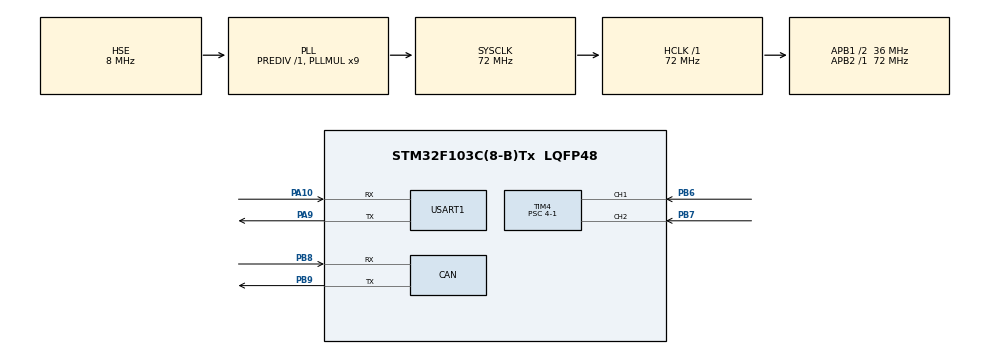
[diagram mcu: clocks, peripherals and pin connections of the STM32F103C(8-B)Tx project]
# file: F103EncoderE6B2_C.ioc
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CAN.CalculateTimeBit=1333
CAN.CalculateTimeQuantum=444.44444444444446
Mcu.Family=STM32F1
Mcu.Name=STM32F103C(8-B)Tx
Mcu.Package=LQFP48
NVIC.CAN1_RX1_IRQn=true\:1\:2\:true\:false\:true\:true\:true
NVIC.PriorityGroup=NVIC_PRIORITYGROUP_2
NVIC.TIM3_IRQn=true\:2\:2\:true\:false\:true\:true\:true
NVIC.TIM4_IRQn=true\:1\:3\:true\:false\:true\:true\:true
PA10.Mode=Asynchronous
PA10.Signal=USART1_RX
PA13.Mode=Serial_Wire
PA13.Signal=SYS_JTMS-SWDIO
PA14.Mode=Serial_Wire
PA14.Signal=SYS_JTCK-SWCLK
PA9.Mode=Asynchronous
PA9.Signal=USART1_TX
PB6.GPIO_PuPd=GPIO_PULLUP
PB6.Signal=S_TIM4_CH1
PB7.GPIO_PuPd=GPIO_PULLUP
PB7.Signal=S_TIM4_CH2
PB8.Mode=Master
PB8.Signal=CAN_RX
PB9.Mode=Master
PB9.Signal=CAN_TX
PD0-OSC_IN.Mode=HSE-External-Oscillator
PD0-OSC_IN.Signal=RCC_OSC_IN
PD1-OSC_OUT.Mode=HSE-External-Oscillator
PD1-OSC_OUT.Signal=RCC_OSC_OUT
ProjectManager.HeapSize=0x200
ProjectManager.StackSize=0x400
ProjectManager.TargetToolchain=MDK-ARM V5
RCC.AHBFreq_Value=72000000
RCC.APB1CLKDivider=RCC_HCLK_DIV2
RCC.APB1Freq_Value=36000000
RCC.APB1TimFreq_Value=72000000
RCC.APB2Freq_Value=72000000
RCC.APB2TimFreq_Value=72000000
RCC.HCLKFreq_Value=72000000
RCC.PLLMUL=RCC_PLL_MUL9
RCC.PLLSourceVirtual=RCC_PLLSOURCE_HSE
RCC.SYSCLKFreq_VALUE=72000000
RCC.SYSCLKSource=RCC_SYSCLKSOURCE_PLLCLK
RCC.USBFreq_Value=72000000
SH.S_TIM4_CH1.0=TIM4_CH1,Encoder_Interface
SH.S_TIM4_CH2.0=TIM4_CH2,Encoder_Interface
TIM3.AutoReloadPreload=TIM_AUTORELOAD_PRELOAD_ENABLE
TIM3.Period=10000
TIM3.Prescaler=72-1
TIM4.CounterMode=TIM_COUNTERMODE_UP
TIM4.EncoderMode=TIM_ENCODERMODE_TI12
TIM4.Period=65535
TIM4.Prescaler=4-1
USART1.VirtualMode=VM_ASYNC
VP_TIM3_VS_ClockSourceINT.Mode=Internal
board=custom

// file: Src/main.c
/* USER CODE BEGIN Header */
/**
  ******************************************************************************
  * @file           : main.c
  * @brief          : Main program body
  ******************************************************************************
  * @attention
  *
  * <h2><center>&copy; Copyright (c) 2020 STMicroelectronics.
  * All rights reserved.</center></h2>
  *
  * This software component is licensed by ST under BSD 3-Clause license,
  * the "License"; You may not use this file except in compliance with the
  * License. You may obtain a copy of the License at:
  *                        opensource.org/licenses/BSD-3-Clause
  *
  ******************************************************************************
  */
/* USER CODE END Header */

#include "main.h"

/* USER CODE BEGIN Includes */
#include "encoderE6B2.h"
/* USER CODE END Includes */

CAN_HandleTypeDef hcan;

TIM_HandleTypeDef htim3;
TIM_HandleTypeDef htim4;

UART_HandleTypeDef huart1;

/* USER CODE BEGIN PV */
	uint16_t cnt = 0;
	uint8_t string1[] = {"hello\r\n"};
/* USER CODE END PV */

void SystemClock_Config(void);
static void MX_GPIO_Init(void);
static void MX_TIM4_Init(void);
static void MX_USART1_UART_Init(void);
static void MX_CAN_Init(void);
static void MX_TIM3_Init(void);

int main(void)
{

  /* MCU Configuration--------------------------------------------------------*/

  /* Reset of all peripherals, Initializes the Flash interface and the Systick. */
  HAL_Init();

  /* Configure the system clock */
  SystemClock_Config();

  /* Initialize all configured peripherals */
  MX_GPIO_Init();
  MX_TIM4_Init();
  MX_USART1_UART_Init();
  MX_CAN_Init();
  MX_TIM3_Init();

  /* Infinite loop */
  /* USER CODE BEGIN WHILE */
  while (1)
  {
	 cnt = __HAL_TIM_GET_COUNTER(&htim4);

	 //Circle_Print();

	 HAL_UART_Transmit(&huart1, (uint8_t *)&cnt, 2, 100);
	 //HAL_UART_Transmit(&huart1, (uint8_t *)&string1, 8, 100);
	 HAL_Delay(100);
    /* USER CODE END WHILE */

  }
}

void SystemClock_Config(void)
{
  RCC_OscInitTypeDef RCC_OscInitStruct = {0};
  RCC_ClkInitTypeDef RCC_ClkInitStruct = {0};

  /** Initializes the CPU, AHB and APB busses clocks
  */
  RCC_OscInitStruct.OscillatorType = RCC_OSCILLATORTYPE_HSE;
  RCC_OscInitStruct.HSEState = RCC_HSE_ON;
  RCC_OscInitStruct.HSEPredivValue = RCC_HSE_PREDIV_DIV1;
  RCC_OscInitStruct.HSIState = RCC_HSI_ON;
  RCC_OscInitStruct.PLL.PLLState = RCC_PLL_ON;
  RCC_OscInitStruct.PLL.PLLSource = RCC_PLLSOURCE_HSE;
  RCC_OscInitStruct.PLL.PLLMUL = RCC_PLL_MUL9;
  if (HAL_RCC_OscConfig(&RCC_OscInitStruct) != HAL_OK)
  {
    Error_Handler();
  }
  /** Initializes the CPU, AHB and APB busses clocks
  */
  RCC_ClkInitStruct.ClockType = RCC_CLOCKTYPE_HCLK|RCC_CLOCKTYPE_SYSCLK
                              |RCC_CLOCKTYPE_PCLK1|RCC_CLOCKTYPE_PCLK2;
  RCC_ClkInitStruct.SYSCLKSource = RCC_SYSCLKSOURCE_PLLCLK;
  RCC_ClkInitStruct.AHBCLKDivider = RCC_SYSCLK_DIV1;
  RCC_ClkInitStruct.APB1CLKDivider = RCC_HCLK_DIV2;
  RCC_ClkInitStruct.APB2CLKDivider = RCC_HCLK_DIV1;

  if (HAL_RCC_ClockConfig(&RCC_ClkInitStruct, FLASH_LATENCY_2) != HAL_OK)
  {
    Error_Handler();
  }
}

static void MX_CAN_Init(void)
{

  hcan.Instance = CAN1;
  hcan.Init.Prescaler = 16;
  hcan.Init.Mode = CAN_MODE_NORMAL;
  hcan.Init.SyncJumpWidth = CAN_SJW_1TQ;
  hcan.Init.TimeSeg1 = CAN_BS1_1TQ;
  hcan.Init.TimeSeg2 = CAN_BS2_1TQ;
  hcan.Init.TimeTriggeredMode = DISABLE;
  hcan.Init.AutoBusOff = DISABLE;
  hcan.Init.AutoWakeUp = DISABLE;
  hcan.Init.AutoRetransmission = DISABLE;
  hcan.Init.ReceiveFifoLocked = DISABLE;
  hcan.Init.TransmitFifoPriority = DISABLE;
  if (HAL_CAN_Init(&hcan) != HAL_OK)
  {
    Error_Handler();
  }

}

static void MX_TIM3_Init(void)
{

  TIM_ClockConfigTypeDef sClockSourceConfig = {0};
  TIM_MasterConfigTypeDef sMasterConfig = {0};

  htim3.Instance = TIM3;
  htim3.Init.Prescaler = 72-1;
  htim3.Init.CounterMode = TIM_COUNTERMODE_UP;
  htim3.Init.Period = 10000;
  htim3.Init.ClockDivision = TIM_CLOCKDIVISION_DIV1;
  htim3.Init.AutoReloadPreload = TIM_AUTORELOAD_PRELOAD_ENABLE;
  if (HAL_TIM_Base_Init(&htim3) != HAL_OK)
  {
    Error_Handler();
  }
  sClockSourceConfig.ClockSource = TIM_CLOCKSOURCE_INTERNAL;
  if (HAL_TIM_ConfigClockSource(&htim3, &sClockSourceConfig) != HAL_OK)
  {
    Error_Handler();
  }
  sMasterConfig.MasterOutputTrigger = TIM_TRGO_RESET;
  sMasterConfig.MasterSlaveMode = TIM_MASTERSLAVEMODE_DISABLE;
  if (HAL_TIMEx_MasterConfigSynchronization(&htim3, &sMasterConfig) != HAL_OK)
  {
    Error_Handler();
  }
  /* USER CODE BEGIN TIM3_Init 2 */

  HAL_TIM_Base_Start_IT(&htim3);
  /* USER CODE END TIM3_Init 2 */

}

static void MX_TIM4_Init(void)
{

  TIM_Encoder_InitTypeDef sConfig = {0};
  TIM_MasterConfigTypeDef sMasterConfig = {0};

  htim4.Instance = TIM4;
  htim4.Init.Prescaler = 4-1;
  htim4.Init.CounterMode = TIM_COUNTERMODE_UP;
  htim4.Init.Period = 65535;
  htim4.Init.ClockDivision = TIM_CLOCKDIVISION_DIV1;
  htim4.Init.AutoReloadPreload = TIM_AUTORELOAD_PRELOAD_DISABLE;
  sConfig.EncoderMode = TIM_ENCODERMODE_TI12;
  sConfig.IC1Polarity = TIM_ICPOLARITY_RISING;
  sConfig.IC1Selection = TIM_ICSELECTION_DIRECTTI;
  sConfig.IC1Prescaler = TIM_ICPSC_DIV1;
  sConfig.IC1Filter = 0;
  sConfig.IC2Polarity = TIM_ICPOLARITY_RISING;
  sConfig.IC2Selection = TIM_ICSELECTION_DIRECTTI;
  sConfig.IC2Prescaler = TIM_ICPSC_DIV1;
  sConfig.IC2Filter = 0;
  if (HAL_TIM_Encoder_Init(&htim4, &sConfig) != HAL_OK)
  {
    Error_Handler();
  }
  sMasterConfig.MasterOutputTrigger = TIM_TRGO_RESET;
  sMasterConfig.MasterSlaveMode = TIM_MASTERSLAVEMODE_DISABLE;
  if (HAL_TIMEx_MasterConfigSynchronization(&htim4, &sMasterConfig) != HAL_OK)
  {
    Error_Handler();
  }
  /* USER CODE BEGIN TIM4_Init 2 */
  HAL_TIM_Encoder_Start(&htim4, TIM_CHANNEL_1 | TIM_CHANNEL_2);
  //HAL_TIM_Encoder_Start_IT(&htim4, TIM_CHANNEL_1 | TIM_CHANNEL_2);//开启中断

  HAL_TIM_Base_Start_IT(&htim4);
  /* USER CODE END TIM4_Init 2 */

}

static void MX_USART1_UART_Init(void)
{

  huart1.Instance = USART1;
  huart1.Init.BaudRate = 115200;
  huart1.Init.WordLength = UART_WORDLENGTH_8B;
  huart1.Init.StopBits = UART_STOPBITS_1;
  huart1.Init.Parity = UART_PARITY_NONE;
  huart1.Init.Mode = UART_MODE_TX_RX;
  huart1.Init.HwFlowCtl = UART_HWCONTROL_NONE;
  huart1.Init.OverSampling = UART_OVERSAMPLING_16;
  if (HAL_UART_Init(&huart1) != HAL_OK)
  {
    Error_Handler();
  }

}

static void MX_GPIO_Init(void)
{

  /* GPIO Ports Clock Enable */
  __HAL_RCC_GPIOD_CLK_ENABLE();
  __HAL_RCC_GPIOA_CLK_ENABLE();
  __HAL_RCC_GPIOB_CLK_ENABLE();

}

void Error_Handler(void)
{
}

/************************ (C) COPYRIGHT STMicroelectronics *****END OF FILE****/
